# CH641 register map
Vendor: WCH Ltd.; File version: 1.1
Registers are 32-bit, read-write, reset 0x0 unless marked. A register's access mark holds for its fields unless they carry their own. Offsets are from the block's base; [hi:lo] are bit positions.

## WWDG — Window watchdog
Base 0x40002C00
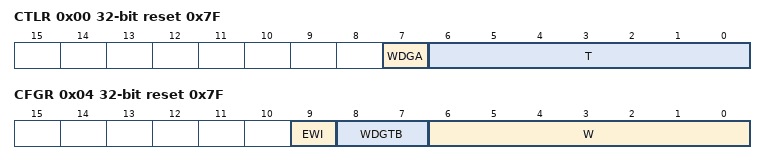
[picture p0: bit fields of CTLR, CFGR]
0x00 CTLR reset 0x7F — Control register (WWDG_CR)
  [7] WDGA — Activation bit
  [6:0] T — 7-bit counter (MSB to LSB)
0x04 CFGR reset 0x7F — Configuration register (WWDG_CFR)
  [9] EWI — Early Wakeup Interrupt
  [8:7] WDGTB — Timer Base
  [6:0] W — 7-bit window value
0x08 STATR — Status register (WWDG_SR)
  [0] EWIF — Early Wakeup Interrupt Flag

## TIM2 — General purpose timer
Base 0x40000000
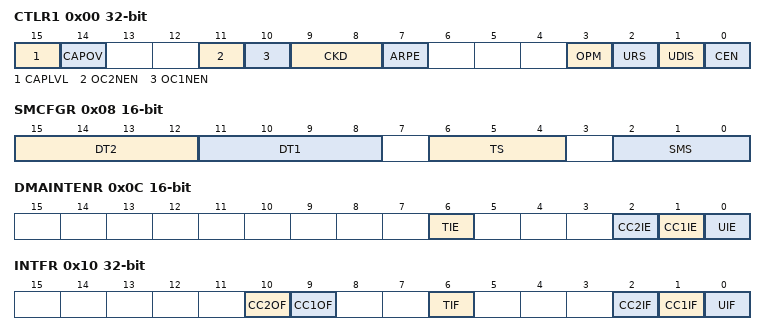
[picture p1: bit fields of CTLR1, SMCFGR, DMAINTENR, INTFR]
0x00 CTLR1 — control register 1
  [15] CAPLVL — Timer capture level indication enable
  [14] CAPOV — Timer capture value configuration enable
  [11] OC2NEN — Channel 2 dead-time fraction enable
  [10] OC1NEN — Channel 1 dead-time fraction enable
  [9:8] CKD — Clock division
  [7] ARPE — Auto-reload preload enable
  [3] OPM — One-pulse mode
  [2] URS — Update request source
  [1] UDIS — Update disable
  [0] CEN — Counter enable
0x08 SMCFGR 16-bit — slave mode control register
  [15:12] DT2 — Channel 2 dead-time setting
  [11:8] DT1 — Channel 1 dead-time setting
  [6:4] TS — Trigger selection
  [2:0] SMS — Slave mode selection
0x0C DMAINTENR 16-bit — DMA/Interrupt enable register
  [6] TIE — Trigger interrupt enable
  [2] CC2IE — Capture/Compare 2 interrupt enable
  [1] CC1IE — Capture/Compare 1 interrupt enable
  [0] UIE — Update interrupt enable
0x10 INTFR — status register
  [10] CC2OF — Capture/compare 2 overcapture flag
  [9] CC1OF — Capture/Compare 1 overcapture flag
  [6] TIF — Trigger interrupt flag
  [2] CC2IF — Capture/Compare 2 interrupt flag
  [1] CC1IF — Capture/compare 1 interrupt flag
  [0] UIF — Update interrupt flag
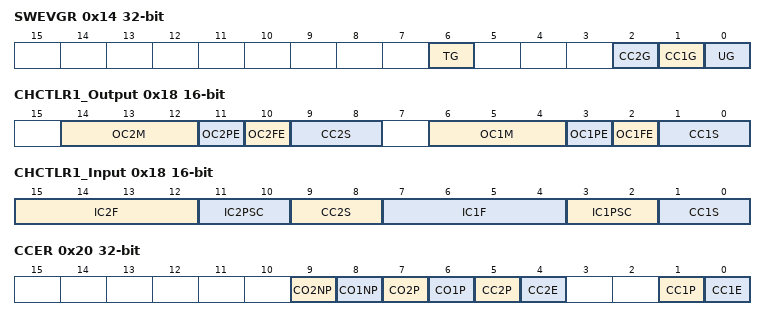
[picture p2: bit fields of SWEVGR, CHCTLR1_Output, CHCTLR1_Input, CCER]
0x14 SWEVGR wo — event generation register
  [6] TG — Trigger generation
  [2] CC2G — Capture/compare 2 generation
  [1] CC1G — Capture/compare 1 generation
  [0] UG — Update generation
0x18 CHCTLR1_Output 16-bit — capture/compare mode register 1 (output mode)
  [14:12] OC2M — Output compare channel 2 mode
  [11] OC2PE — Compare capture register 1 preload enable
  [10] OC2FE — Output compare channel 2 fast enable
  [9:8] CC2S — Capture/Compare channel 2 input selection
  [6:4] OC1M — Output compare 1 mode
  [3] OC1PE — Output compare 1 preload enable
  [2] OC1FE — Output compare 1 fast enable
  [1:0] CC1S — Capture/Compare 1 selection
0x18 CHCTLR1_Input 16-bit (alternate view of CHCTLR1_Output) — capture/compare mode register 1 (input mode)
  [15:12] IC2F — Input capture 2 filter
  [11:10] IC2PSC — Input capture 2 prescaler
  [9:8] CC2S — Capture/compare 2 selection
  [7:4] IC1F — Input capture 1 filter
  [3:2] IC1PSC — Input capture 1 prescaler
  [1:0] CC1S — Capture/Compare 1 selection
0x20 CCER — capture/compare enable register
  [9] CO2NP — Channel 2 complements the channel output polarity
  [8] CO1NP — Channel 1 complements the channel output polarity
  [7] CO2P — Channel 2 dead-time output polarity
  [6] CO1P — Channel 1 dead-time output polarity
  [5] CC2P — Capture/Compare channel 2 output Polarity
  [4] CC2E — Capture/Compare channel 2 output enable
  [1] CC1P — Capture/Compare channel 1 output Polarity
  [0] CC1E — Capture/Compare channel 1 output enable
0x24 CNT — counter
  [15:0] CNT — counter value
0x28 PSC — prescaler
  [15:0] PSC — Prescaler value
0x2C ATRLR — auto-reload register
  [15:0] ATRLR — Auto-reload value
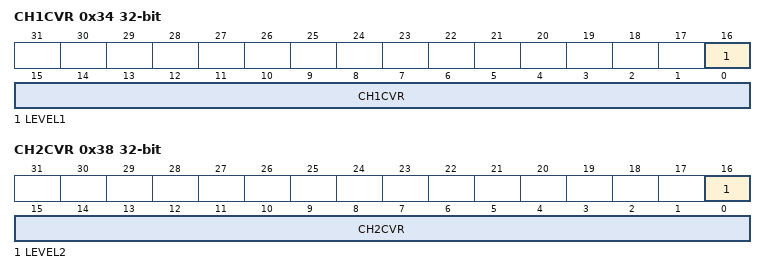
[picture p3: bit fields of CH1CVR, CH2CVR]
0x34 CH1CVR — capture/compare register 1
  [16] LEVEL1 — Level indicating bit
  [15:0] CH1CVR — Capture/Compare 1 value
0x38 CH2CVR — capture/compare register 2
  [16] LEVEL2 — Level indicating bit
  [15:0] CH2CVR — Capture/Compare 2 value

## I2C1 — Inter integrated circuit
Base 0x40005400
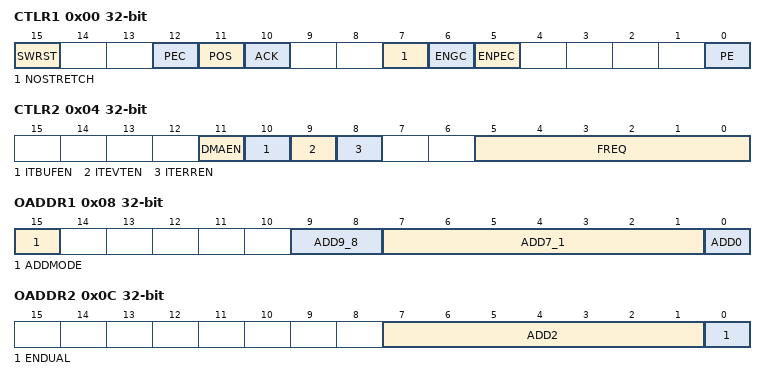
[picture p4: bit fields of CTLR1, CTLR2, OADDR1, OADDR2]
0x00 CTLR1 — Control register 1
  [15] SWRST — Software reset
  [12] PEC — Packet error checking
  [11] POS — Acknowledge/PEC Position (for data reception)
  [10] ACK — Acknowledge enable
  [7] NOSTRETCH — Clock stretching disable (Slave mode)
  [6] ENGC — General call enable
  [5] ENPEC — PEC enable
  [0] PE — Peripheral enable
0x04 CTLR2 — Control register 2
  [11] DMAEN — DMA requests enable
  [10] ITBUFEN — Buffer interrupt enable
  [9] ITEVTEN — Event interrupt enable
  [8] ITERREN — Error interrupt enable
  [5:0] FREQ — Peripheral clock frequency
0x08 OADDR1 — Own address register 1
  [15] ADDMODE — Addressing mode (slave mode)
  [9:8] ADD9_8 — Interface address
  [7:1] ADD7_1 — Interface address
  [0] ADD0 — Interface address
0x0C OADDR2 — Own address register 2
  [7:1] ADD2 — Interface address
  [0] ENDUAL — Dual addressing mode enable
0x10 DATAR — Data register
  [7:0] DR — 8-bit data register
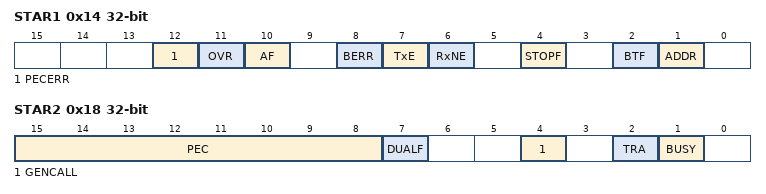
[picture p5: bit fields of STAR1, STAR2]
0x14 STAR1 access per field — Status register 1
  [12] PECERR rw — PEC Error in reception
  [11] OVR rw — Overrun/Underrun
  [10] AF rw — Acknowledge failure
  [8] BERR rw — Bus error
  [7] TxE ro — Data register empty (transmitters)
  [6] RxNE ro — Data register not empty (receivers)
  [4] STOPF ro — Stop detection (slave mode)
  [2] BTF ro — Byte transfer finished
  [1] ADDR ro — Address sent (master mode)/matched (slave mode)
0x18 STAR2 ro — Status register 2
  [15:8] PEC — acket error checking register
  [7] DUALF — Dual flag (Slave mode)
  [4] GENCALL — General call address (Slave mode)
  [2] TRA — Transmitter/receiver
  [1] BUSY — Bus busy
